AUTOSAR XML (schema 00046)
package /Runnables1
  sender receiver interface SRI_Throttle
    data Throttle_CMD: type=uint32
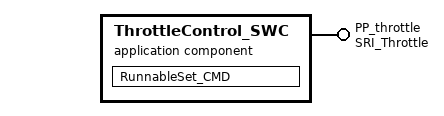
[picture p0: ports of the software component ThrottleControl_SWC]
  application sw component type ThrottleControl_SWC
    provide port PP_throttle: provided-interface=SRI_Throttle
    behavior ThrottleController_behavior
      runnable RunnableSet_CMD: symbol=Set_CMD
        data-write-access:
          access CMD_Data: accessed-variable=PP_throttle.Throttle_CMD
